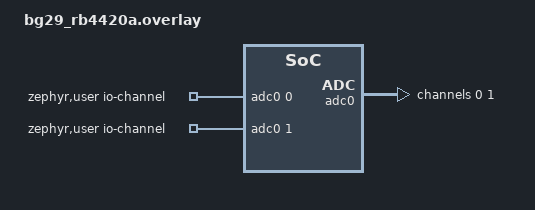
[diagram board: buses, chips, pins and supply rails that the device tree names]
/*
 * Copyright (c) 2025 Silicon Laboratories Inc.
 *
 * SPDX-License-Identifier: Apache-2.0
 */

#include "dt-bindings/adc/silabs-adc.h"

/ {
	zephyr,user {
		io-channels = <&adc0 0>, <&adc0 1>;
	};
};

&adc0 {
	status = "okay";
	#address-cells = <1>;
	#size-cells = <0>;

	channel@0 {
		reg = <0>;
		zephyr,gain = "ADC_GAIN_1";
		zephyr,reference = "ADC_REF_INTERNAL";
		zephyr,acquisition-time = <ADC_ACQ_TIME_DEFAULT>;
		zephyr,resolution = <12>;
		zephyr,input-positive = <IADC_INPUT_IOVDD>;
	};

	channel@1 {
		reg = <1>;
		zephyr,gain = "ADC_GAIN_1";
		zephyr,reference = "ADC_REF_INTERNAL";
		zephyr,acquisition-time = <ADC_ACQ_TIME_DEFAULT>;
		zephyr,resolution = <12>;
		zephyr,input-positive = <IADC_INPUT_VBAT>;
	};
};
